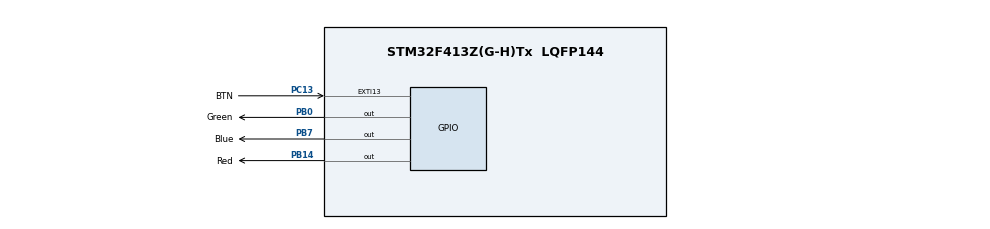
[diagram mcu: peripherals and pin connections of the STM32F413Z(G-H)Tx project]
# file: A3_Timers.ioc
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Mcu.Family=STM32F4
Mcu.Name=STM32F413Z(G-H)Tx
Mcu.Package=LQFP144
NVIC.EXTI15_10_IRQn=true\:0\:0\:false\:false\:true\:true\:true\:true
NVIC.PriorityGroup=NVIC_PRIORITYGROUP_4
NVIC.TIM2_IRQn=true\:0\:0\:false\:false\:true\:true\:true\:true
PB0.GPIO_Label=Green
PB0.Signal=GPIO_Output
PB14.GPIO_Label=Red
PB14.Signal=GPIO_Output
PB7.GPIO_Label=Blue
PB7.Signal=GPIO_Output
PC13.GPIO_Label=BTN
PC13.GPIO_PuPd=GPIO_PULLDOWN
PC13.Signal=GPXTI13
ProjectManager.HeapSize=0x200
ProjectManager.StackSize=0x400
ProjectManager.TargetToolchain=STM32CubeIDE
RCC.CortexFreq_Value=16000000
RCC.USBFreq_Value=96000000
RCC.VCOOutputFreq_Value=192000000
TIM2.AutoReloadPreload=TIM_AUTORELOAD_PRELOAD_ENABLE
TIM2.Period=500-1
TIM2.Prescaler=16000-1
VP_TIM2_VS_ClockSourceINT.Mode=Internal
board=custom

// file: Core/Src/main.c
/* USER CODE BEGIN Header */
/**
  ******************************************************************************
  * @file           : main.c
  * @brief          : Main program body
  ******************************************************************************
  * @attention
  *
  * Copyright (c) 2024 STMicroelectronics.
  * All rights reserved.
  *
  * This software is licensed under terms that can be found in the LICENSE file
  * in the root directory of this software component.
  * If no LICENSE file comes with this software, it is provided AS-IS.
  *
  ******************************************************************************
  */
/* USER CODE END Header */
#include "main.h"

TIM_HandleTypeDef htim2;

/* USER CODE BEGIN PV */
uint8_t currentLED = 0; // 0: verde, 1: azul, 2: rojo
uint32_t frequencies[] = { 500-1, 250-1, 125-1 }; // frecuencias de 1Hz, 2Hz y 4Hz (en milisegundos)
uint16_t LED_PIN[] = { Green_Pin, Blue_Pin, Red_Pin };
/* USER CODE END PV */

void SystemClock_Config(void);
static void MX_GPIO_Init(void);
static void MX_TIM2_Init(void);

int main(void)
{

  /* MCU Configuration--------------------------------------------------------*/

  /* Reset of all peripherals, Initializes the Flash interface and the Systick. */
  HAL_Init();

  /* Configure the system clock */
  SystemClock_Config();

  /* Initialize all configured peripherals */
  MX_GPIO_Init();
  MX_TIM2_Init();
  /* USER CODE BEGIN 2 */
  // empezar las interrupciones del temporizador
  HAL_TIM_Base_Start_IT(&htim2);
  // encender el LED verde inicialmente
  HAL_GPIO_WritePin(GPIOB, LED_PIN[currentLED], GPIO_PIN_SET);
  /* USER CODE END 2 */

  /* Infinite loop */
  while (1)
  {

  }
}

void SystemClock_Config(void)
{
  RCC_OscInitTypeDef RCC_OscInitStruct = {0};
  RCC_ClkInitTypeDef RCC_ClkInitStruct = {0};

  /** Configure the main internal regulator output voltage
  */
  __HAL_RCC_PWR_CLK_ENABLE();
  __HAL_PWR_VOLTAGESCALING_CONFIG(PWR_REGULATOR_VOLTAGE_SCALE1);

  /** Initializes the RCC Oscillators according to the specified parameters
  * in the RCC_OscInitTypeDef structure.
  */
  RCC_OscInitStruct.OscillatorType = RCC_OSCILLATORTYPE_HSI;
  RCC_OscInitStruct.HSIState = RCC_HSI_ON;
  RCC_OscInitStruct.HSICalibrationValue = RCC_HSICALIBRATION_DEFAULT;
  RCC_OscInitStruct.PLL.PLLState = RCC_PLL_NONE;
  if (HAL_RCC_OscConfig(&RCC_OscInitStruct) != HAL_OK)
  {
    Error_Handler();
  }

  /** Initializes the CPU, AHB and APB buses clocks
  */
  RCC_ClkInitStruct.ClockType = RCC_CLOCKTYPE_HCLK|RCC_CLOCKTYPE_SYSCLK
                              |RCC_CLOCKTYPE_PCLK1|RCC_CLOCKTYPE_PCLK2;
  RCC_ClkInitStruct.SYSCLKSource = RCC_SYSCLKSOURCE_HSI;
  RCC_ClkInitStruct.AHBCLKDivider = RCC_SYSCLK_DIV1;
  RCC_ClkInitStruct.APB1CLKDivider = RCC_HCLK_DIV1;
  RCC_ClkInitStruct.APB2CLKDivider = RCC_HCLK_DIV1;

  if (HAL_RCC_ClockConfig(&RCC_ClkInitStruct, FLASH_LATENCY_0) != HAL_OK)
  {
    Error_Handler();
  }
}

static void MX_TIM2_Init(void)
{

  TIM_ClockConfigTypeDef sClockSourceConfig = {0};
  TIM_MasterConfigTypeDef sMasterConfig = {0};

  htim2.Instance = TIM2;
  htim2.Init.Prescaler = 16000-1;
  htim2.Init.CounterMode = TIM_COUNTERMODE_UP;
  htim2.Init.Period = 500-1;
  htim2.Init.ClockDivision = TIM_CLOCKDIVISION_DIV1;
  htim2.Init.AutoReloadPreload = TIM_AUTORELOAD_PRELOAD_ENABLE;
  if (HAL_TIM_Base_Init(&htim2) != HAL_OK)
  {
    Error_Handler();
  }
  sClockSourceConfig.ClockSource = TIM_CLOCKSOURCE_INTERNAL;
  if (HAL_TIM_ConfigClockSource(&htim2, &sClockSourceConfig) != HAL_OK)
  {
    Error_Handler();
  }
  sMasterConfig.MasterOutputTrigger = TIM_TRGO_RESET;
  sMasterConfig.MasterSlaveMode = TIM_MASTERSLAVEMODE_DISABLE;
  if (HAL_TIMEx_MasterConfigSynchronization(&htim2, &sMasterConfig) != HAL_OK)
  {
    Error_Handler();
  }

}

static void MX_GPIO_Init(void)
{
  GPIO_InitTypeDef GPIO_InitStruct = {0};

  /* GPIO Ports Clock Enable */
  __HAL_RCC_GPIOC_CLK_ENABLE();
  __HAL_RCC_GPIOB_CLK_ENABLE();

  /*Configure GPIO pin Output Level */
  HAL_GPIO_WritePin(GPIOB, Green_Pin|Red_Pin|Blue_Pin, GPIO_PIN_RESET);

  /*Configure GPIO pin : BTN_Pin */
  GPIO_InitStruct.Pin = BTN_Pin;
  GPIO_InitStruct.Mode = GPIO_MODE_IT_RISING;
  GPIO_InitStruct.Pull = GPIO_PULLDOWN;
  HAL_GPIO_Init(BTN_GPIO_Port, &GPIO_InitStruct);

  /*Configure GPIO pins : Green_Pin Red_Pin Blue_Pin */
  GPIO_InitStruct.Pin = Green_Pin|Red_Pin|Blue_Pin;
  GPIO_InitStruct.Mode = GPIO_MODE_OUTPUT_PP;
  GPIO_InitStruct.Pull = GPIO_NOPULL;
  GPIO_InitStruct.Speed = GPIO_SPEED_FREQ_LOW;
  HAL_GPIO_Init(GPIOB, &GPIO_InitStruct);

  /* EXTI interrupt init*/
  HAL_NVIC_SetPriority(EXTI15_10_IRQn, 0, 0);
  HAL_NVIC_EnableIRQ(EXTI15_10_IRQn);

}

/* USER CODE BEGIN 4 */
void HAL_GPIO_EXTI_Callback(uint16_t GPIO_Pin) {
    if (GPIO_Pin == BTN_Pin) { // si presionamos el botón
        // apagar el LED actual
        HAL_GPIO_WritePin(GPIOB, LED_PIN[currentLED], GPIO_PIN_RESET);

        // seleccionar el LED siguiente
        currentLED = (currentLED + 1) % 3;

        // cambiar la frecuencia de interrupción de TIM2
        __HAL_TIM_SET_AUTORELOAD(&htim2, frequencies[currentLED]);

        // encender el nuevo LED
        HAL_GPIO_WritePin(GPIOB, LED_PIN[currentLED], GPIO_PIN_SET);
    }
}

void HAL_TIM_PeriodElapsedCallback(TIM_HandleTypeDef *htim) {
    if (htim == &htim2) {
        // encender o apagar el led
        HAL_GPIO_TogglePin(GPIOB, LED_PIN[currentLED]);
    }
}
/* USER CODE END 4 */

void Error_Handler(void)
{
  __disable_irq();
  while (1)
  {
  }
}
